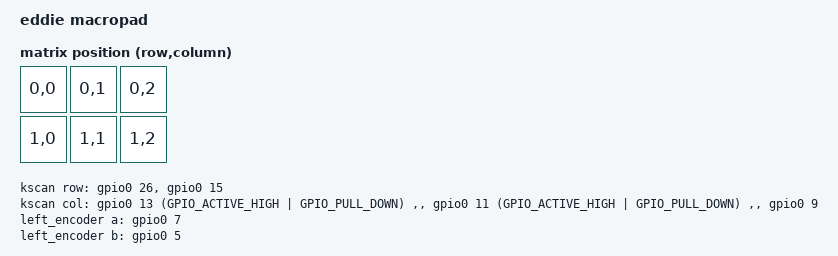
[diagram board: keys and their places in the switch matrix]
// This file was generated from a template. Edit it to match your keyboard.
// See https://docs.zephyrproject.org/4.1.0/hardware/porting/board_porting.html
// and https://zmk.dev/docs/development/hardware-integration/new-shield for more
// instructions.

/dts-v1/;
#include <dt-bindings/zmk/matrix_transform.h>
#include <dt-bindings/input/input.h>
#include "eddie_macropad-pinctrl.dtsi"
#include "eddie_macropad-layouts.dtsi"

/ {
    model = "eddie macropad";
    compatible = "eddie_macropad";

    chosen {
        zmk,physical-layout = &default_layout;
    };

    kscan: kscan {
        // If the hardware does not use a switch matrix, change this to the
        // appropriate driver and update the properties below to match.
        // See https://zmk.dev/docs/config/kscan for supported key scan drivers.
        compatible = "zmk,kscan-gpio-matrix";
        // Set this to "col2row" or "row2col" to match the hardware. If using
        // "row2col", change the col-gpios to (GPIO_ACTIVE_HIGH | GPIO_PULL_DOWN)
        // and the row-gpios to GPIO_ACTIVE_HIGH.
        diode-direction = "row2col";
        wakeup-source;

        // Replace these comments with the GPIO pins in the matrix.
        // See https://zmk.dev/docs/development/hardware-integration/new-shield#shield-overlays
        col-gpios
            = <&gpio0 13 (GPIO_ACTIVE_HIGH | GPIO_PULL_DOWN)
            , <&gpio0 11 (GPIO_ACTIVE_HIGH | GPIO_PULL_DOWN)
            , <&gpio0 9 (GPIO_ACTIVE_HIGH | GPIO_PULL_DOWN)
            ;

        row-gpios
            = <&gpio0 26 GPIO_ACTIVE_HIGH>
            , <&gpio0 15 GPIO_ACTIVE_HIGH>
            ;
    };

    left_encoder: encoder_left {
        compatible = "alps,ec11";
        label = "LEFT_ENCODER";
        a-gpios = <&gpio0 7 (GPIO_ACTIVE_HIGH | GPIO_PULL_UP)>;
        b-gpios = <&gpio0 5 (GPIO_ACTIVE_HIGH | GPIO_PULL_UP)>;
        resolution = <4>; // Use 20 for older/different methods, 4 is common for 20 pulse per 360deg with detents
        status = "okay";
    };

    sensors {
        compatible = "zmk,keymap-sensors";
        sensors = <&left_encoder>;
        triggers-per-rotation = <20>; // Standard EC11 pulses per rotation
    };

    default_transform: default_transform {
        // See https://zmk.dev/docs/development/hardware-integration/new-shield#matrix-transform
        // for how to configure this
        compatible = "zmk,matrix-transform";
        columns = <3>;
        rows = <2>;

        map = <
            RC(0, 0) RC(0, 1) RC(0, 2)
            RC(1, 0) RC(1, 1) RC(1, 2)
        >;
    };
};
